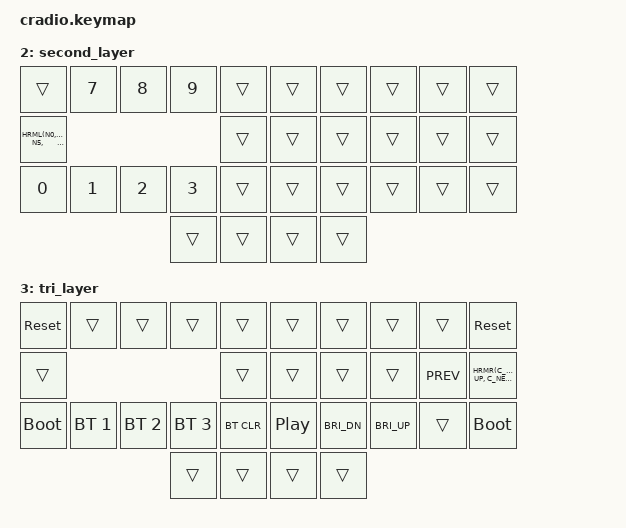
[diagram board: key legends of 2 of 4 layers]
// Copyright (c) 2022 The ZMK Contributors
// SPDX-License-Identifier: MIT

// NOTE: If it won't re-pair with Macbook:
// 1. Remove from MacOS
// 2. BT_CLR every profile
// 3. Connect in MacOS

#include <behaviors.dtsi>
#include <dt-bindings/zmk/keys.h>
#include <dt-bindings/zmk/bt.h>

#define MOD_MORPH(NAME, MOD, BINDING_1, BINDING_2) \
  NAME { \
    compatible = "zmk,behavior-mod-morph"; \
    #binding-cells = <0>; \
    mods = <(MOD_L##MOD | MOD_R##MOD)>; \
    bindings = BINDING_1, BINDING_2; \
  };

#define COMBO(NAME, BINDINGS, KEYPOS, TIMEOUT, IDLE) \
  combo_##NAME { \
    timeout-ms = <TIMEOUT>; \
    bindings = <BINDINGS>; \
    key-positions = <KEYPOS>; \
  };

#define COMBO_IDLE_FAST 100
#define COMBO_IDLE_SLOW 50

#define COMBO_TERM_FAST 20
#define COMBO_TERM_SLOW 30

#define KEYS_L 0 1 2 3 4 10 11 12 13 14 20 21 22 23 24 30 31
#define KEYS_R 5 6 7 8 9 15 16 17 18 19 25 26 27 28 29 32 33

// Home row mods macro
#define HRML(k1,k2,k3,k4) &lh_pht LGUI k1  &lh_pht LALT k2  &lh_pht LCTRL k3  &lh_pht LSHFT k4
#define HRMR(k1,k2,k3,k4) &rh_pht RSHFT k1  &rh_pht RCTRL k2  &rh_pht RALT k3  &rh_pht RGUI k4

&sk {
    quick-release;
};

/ {
    behaviors {
        lh_pht: left_positional_hold_tap {
            compatible = "zmk,behavior-hold-tap";
            #binding-cells = <2>;
            flavor = "balanced";
            tapping-term-ms = <200>;
            quick-tap-ms = <150>;
            require-prior-idle-ms = <120>;
            bindings = <&kp>, <&kp>;
            hold-trigger-key-positions = <KEYS_R>;
            hold-trigger-on-release;
        };

        rh_pht: right_positional_hold_tap {
            compatible = "zmk,behavior-hold-tap";
            #binding-cells = <2>;
            flavor = "balanced";
            tapping-term-ms = <300>;
            quick-tap-ms = <150>;
            require-prior-idle-ms = <120>;
            bindings = <&kp>, <&kp>;
            hold-trigger-key-positions = <KEYS_L>;
            hold-trigger-on-release;
        };

        ss_cw: sticky_shift_caps_word {
            compatible = "zmk,behavior-tap-dance";
            #binding-cells = <0>;
            tapping-term-ms = <200>;
            bindings = <&sk LSHIFT>, <&caps_word>;
        };

        lpar_lt: MOD_MORPH(lpar_lt, SFT, <&kp LPAR>, <&kp LT>)
        rpar_gt: MOD_MORPH(rpar_gt, SFT, <&kp RPAR>, <&kp GT>)

        comma_semi: MOD_MORPH(comma_semi, SFT, <&kp COMMA>, <&kp SEMICOLON>)
        dot_colon: MOD_MORPH(dot_colon, SFT, <&kp DOT>, <&kp COLON>)
        question_excl: MOD_MORPH(question_excl, SFT, <&kp QUESTION>, <&kp EXCL>)
    };

    conditional_layers {
        compatible = "zmk,conditional-layers";
        tri_layer {
            if-layers = <1 2>;
            then-layer = <3>;
        };
    };

    combos {
        compatible = "zmk,combos";

        // TODO: Maybe put HRMs here too, so I can instantaneously chord them
        COMBO(esc, &kp ESC, 11 12, COMBO_TERM_FAST, COMBO_IDLE_FAST)
        COMBO(tab, &kp TAB, 12 13, COMBO_TERM_FAST, COMBO_IDLE_FAST)

        COMBO(bspc, &kp BSPC, 17 18, COMBO_TERM_FAST, COMBO_IDLE_FAST)
        COMBO(enter, &kp ENTER, 16 17, COMBO_TERM_FAST, COMBO_IDLE_FAST)

        // Symbols
        // top-middle
        COMBO(at,   &kp AT,   1 11, COMBO_TERM_SLOW, COMBO_IDLE_SLOW)
        COMBO(hash, &kp HASH, 2 12, COMBO_TERM_SLOW, COMBO_IDLE_SLOW)
        COMBO(dllr, &kp DLLR, 3 13, COMBO_TERM_SLOW, COMBO_IDLE_SLOW)
        COMBO(prcnt, &kp PRCNT, 4 14, COMBO_TERM_SLOW, COMBO_IDLE_SLOW)

        COMBO(caret, &kp CARET, 5 15, COMBO_TERM_SLOW, COMBO_IDLE_SLOW)
        COMBO(plus, &kp PLUS, 6 16, COMBO_TERM_SLOW, COMBO_IDLE_SLOW)
        COMBO(astk, &kp ASTRK, 7 17, COMBO_TERM_SLOW, COMBO_IDLE_SLOW)
        COMBO(amp, &kp AMPS, 8 18, COMBO_TERM_SLOW, COMBO_IDLE_SLOW)

        // middle-bottom
        COMBO(grave, &kp GRAVE, 11 21, COMBO_TERM_SLOW, COMBO_IDLE_SLOW)
        COMBO(bslh, &kp BSLH, 12 22, COMBO_TERM_SLOW, COMBO_IDLE_SLOW)
        COMBO(equal, &kp EQUAL, 13 23, COMBO_TERM_SLOW, COMBO_IDLE_SLOW)
        COMBO(tilde, &kp TILDE, 14 24, COMBO_TERM_SLOW, COMBO_IDLE_SLOW)

        COMBO(under, &kp UNDER, 15 25, COMBO_TERM_SLOW, COMBO_IDLE_SLOW)
        COMBO(minus, &kp MINUS, 16 26, COMBO_TERM_SLOW, COMBO_IDLE_SLOW)
        COMBO(fslh, &kp FSLH, 17 27, COMBO_TERM_SLOW, COMBO_IDLE_SLOW)
        COMBO(pipe, &kp PIPE, 18 28, COMBO_TERM_SLOW, COMBO_IDLE_SLOW)

        // cols 7-8
        COMBO(lparen, &lpar_lt, 6 7, COMBO_TERM_FAST, COMBO_IDLE_FAST)
        COMBO(rparen, &rpar_gt, 7 8, COMBO_TERM_FAST, COMBO_IDLE_FAST)
        COMBO(lbrkt, &kp LBKT, 26 27, COMBO_TERM_FAST, COMBO_IDLE_FAST)
        COMBO(rbrkt, &kp RBKT, 27 28, COMBO_TERM_FAST, COMBO_IDLE_FAST)
    };

    keymap {
        compatible = "zmk,keymap";
        default_layer {
            bindings = <
        //╭──────────┬──────────┬──────────┬──────────┬──────────╮   ╭──────────┬──────────┬──────────┬──────────┬──────────╮
        //│          │          │          │          │          │   │          │          │          │          │          │
            &kp Q      &kp W      &kp E      &kp R      &kp T          &kp Y      &kp U      &kp I      &kp O      &kp P
        //├──────────┼──────────┼──────────┼──────────┼──────────┤   ├──────────┼──────────┼──────────┼──────────┼──────────┤
        //│          │          │          │          │          │   │          │          │          │          │          │
            HRML(A,        S,         D,         F)     &kp G          &kp H      HRMR(J,        K,         L,        SQT)
        //├──────────┼──────────┼──────────┼──────────┼──────────┤   ├──────────┼──────────┼──────────┼──────────┼──────────┤
        //│          │          │          │          │          │   │          │          │          │          │          │
            &kp Z      &kp X      &kp C      &kp V      &kp B          &kp N      &kp M     &comma_semi &dot_colon &question_excl
        //╰──────────┴──────────┴──────────┼──────────┼──────────┤   ├──────────┼──────────┼──────────┴──────────┴──────────╯
                                             &mo 1      &kp LSHFT      &kp SPACE  &mo 2
        //                                 ╰──────────┴──────────╯   ╰──────────┴──────────╯
            >;
        };

        first_layer {
            bindings = <
        //╭──────────┬──────────┬──────────┬──────────┬──────────╮   ╭──────────┬──────────┬──────────┬──────────┬──────────╮
        //│          │          │          │          │          │   │          │          │          │          │          │
            &kp F12    &kp F7     &kp F8     &kp F9     &trans         &trans     &trans     &trans     &trans     &trans
        //├──────────┼──────────┼──────────┼──────────┼──────────┤   ├──────────┼──────────┼──────────┼──────────┼──────────┤
        //│          │          │          │          │          │   │          │          │          │          │          │
           HRML(F11,       F4,        F5,        F6)    &trans         &kp LEFT   HRMR(DOWN,     UP,        RIGHT, ENTER)
        //├──────────┼──────────┼──────────┼──────────┼──────────┤   ├──────────┼──────────┼──────────┼──────────┼──────────┤
        //│          │          │          │          │          │   │          │          │          │          │          │
            &kp F10    &kp F1     &kp F2     &kp F3     &trans         &kp HOME   &kp PG_DN  &kp PG_UP  &kp END    &trans
        //╰──────────┴──────────┴──────────┼──────────┼──────────┤   ├──────────┼──────────┼──────────┴──────────┴──────────╯
                                             &trans     &trans         &trans     &trans
        //                                 ╰──────────┴──────────╯   ╰──────────┴──────────╯
            >;
        };

        second_layer {
            bindings = <
        //╭──────────┬──────────┬──────────┬──────────┬──────────╮   ╭──────────┬──────────┬──────────┬──────────┬──────────╮
        //│          │          │          │          │          │   │          │          │          │          │          │
            &trans     &kp N7     &kp N8     &kp N9     &trans         &trans     &trans     &trans     &trans     &trans
        //├──────────┼──────────┼──────────┼──────────┼──────────┤   ├──────────┼──────────┼──────────┼──────────┼──────────┤
        //│          │          │          │          │          │   │          │          │          │          │          │
            HRML(N0,       N4,        N5,        N6)    &trans         &trans     &trans     &trans     &trans     &trans
        //├──────────┼──────────┼──────────┼──────────┼──────────┤   ├──────────┼──────────┼──────────┼──────────┼──────────┤
        //│          │          │          │          │          │   │          │          │          │          │          │
            &kp N0     &kp N1     &kp N2     &kp N3     &trans         &trans     &trans     &trans     &trans     &trans
        //╰──────────┴──────────┴──────────┼──────────┼──────────┤   ├──────────┼──────────┼──────────┴──────────┴──────────╯
                                             &trans     &trans         &trans     &trans
        //                                 ╰──────────┴──────────╯   ╰──────────┴──────────╯
            >;
        };

        tri_layer {
            bindings = <
        //╭──────────┬──────────┬──────────┬──────────┬──────────╮   ╭──────────┬──────────┬──────────┬──────────┬──────────╮
        //│ RESET    │          │          │          │          │   │          │          │          │          │  RESET   │
           &sys_reset  &trans     &trans     &trans     &trans         &trans     &trans     &trans     &trans    &sys_reset
        //├──────────┼──────────┼──────────┼──────────┼──────────┤   ├──────────┼──────────┼──────────┼──────────┼──────────┤
        //│          │          │          │          │          │   │          │          │          │          │          │
            &trans     &trans     &trans     &trans     &trans         &kp C_PREV HRMR(C_VOL_DN, C_VOL_UP, C_NEXT, C_MUTE)
        //├──────────┼──────────┼──────────┼──────────┼──────────┤   ├──────────┼──────────┼──────────┼──────────┼──────────┤
        //│          │          │          │          │          │   │          │          │          │          │          │
       &bootloader &bt BT_SEL 1 &bt BT_SEL 2 &bt BT_SEL 3 &bt BT_CLR   &kp C_PP &kp C_BRI_DN &kp C_BRI_UP &trans  &bootloader
        //╰──────────┴──────────┴──────────┼──────────┼──────────┤   ├──────────┼──────────┼──────────┴──────────┴──────────╯
                                             &trans     &trans         &trans     &trans
        //                                 ╰──────────┴──────────╯   ╰──────────┴──────────╯
            >;
        };
    };
};
